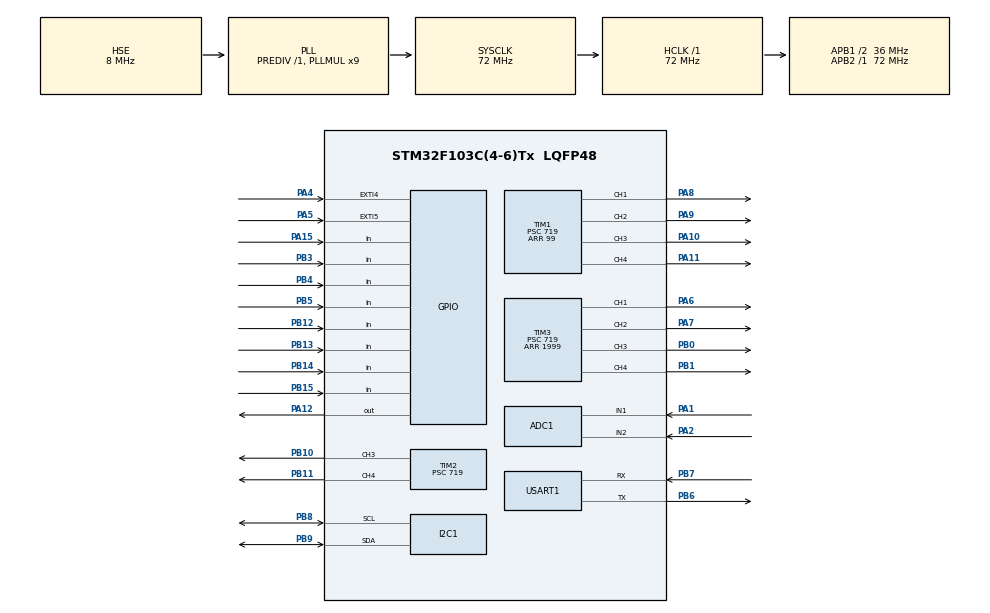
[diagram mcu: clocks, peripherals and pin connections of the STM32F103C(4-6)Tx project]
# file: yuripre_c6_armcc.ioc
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ADC1.Channel-0\#ChannelRegularConversion=ADC_CHANNEL_1
ADC1.NbrOfConversionFlag=1
ADC1.Rank-0\#ChannelRegularConversion=1
ADC1.SamplingTime-0\#ChannelRegularConversion=ADC_SAMPLETIME_1CYCLE_5
ADC1.master=1
Mcu.Family=STM32F1
Mcu.Name=STM32F103C(4-6)Tx
Mcu.Package=LQFP48
NVIC.PriorityGroup=NVIC_PRIORITYGROUP_4
PA1.Signal=ADCx_IN1
PA10.Signal=S_TIM1_CH3
PA11.Signal=S_TIM1_CH4
PA12.Signal=GPIO_Output
PA13.Mode=Serial_Wire
PA13.Signal=SYS_JTMS-SWDIO
PA14.Mode=Serial_Wire
PA14.Signal=SYS_JTCK-SWCLK
PA15.GPIO_PuPd=GPIO_PULLUP
PA15.Signal=GPIO_Input
PA2.Signal=ADCx_IN2
PA4.GPIO_ModeDefaultEXTI=GPIO_MODE_IT_FALLING
PA4.GPIO_PuPd=GPIO_PULLUP
PA4.Signal=GPXTI4
PA5.GPIO_ModeDefaultEXTI=GPIO_MODE_IT_FALLING
PA5.GPIO_PuPd=GPIO_PULLUP
PA5.Signal=GPXTI5
PA6.Signal=S_TIM3_CH1
PA7.Signal=S_TIM3_CH2
PA8.Signal=S_TIM1_CH1
PA9.Signal=S_TIM1_CH2
PB0.Signal=S_TIM3_CH3
PB1.Signal=S_TIM3_CH4
PB10.Signal=S_TIM2_CH3
PB11.Signal=S_TIM2_CH4
PB12.GPIO_PuPd=GPIO_PULLUP
PB12.Signal=GPIO_Input
PB13.GPIO_PuPd=GPIO_PULLUP
PB13.Signal=GPIO_Input
PB14.GPIO_PuPd=GPIO_PULLUP
PB14.Signal=GPIO_Input
PB15.GPIO_PuPd=GPIO_PULLUP
PB15.Signal=GPIO_Input
PB3.GPIO_PuPd=GPIO_PULLUP
PB3.Signal=GPIO_Input
PB4.GPIO_PuPd=GPIO_PULLUP
PB4.Signal=GPIO_Input
PB5.GPIO_PuPd=GPIO_PULLUP
PB5.Signal=GPIO_Input
PB6.Mode=Asynchronous
PB6.Signal=USART1_TX
PB7.Mode=Asynchronous
PB7.Signal=USART1_RX
PB8.Mode=I2C
PB8.Signal=I2C1_SCL
PB9.Mode=I2C
PB9.Signal=I2C1_SDA
PD0-OSC_IN.Mode=HSE-External-Oscillator
PD0-OSC_IN.Signal=RCC_OSC_IN
PD1-OSC_OUT.Mode=HSE-External-Oscillator
PD1-OSC_OUT.Signal=RCC_OSC_OUT
ProjectManager.HeapSize=0x200
ProjectManager.StackSize=0x400
ProjectManager.TargetToolchain=MDK-ARM V5.32
RCC.ADCPresc=RCC_ADCPCLK2_DIV6
RCC.AHBFreq_Value=72000000
RCC.APB1CLKDivider=RCC_HCLK_DIV2
RCC.APB1Freq_Value=36000000
RCC.APB1TimFreq_Value=72000000
RCC.APB2Freq_Value=72000000
RCC.APB2TimFreq_Value=72000000
RCC.HCLKFreq_Value=72000000
RCC.PLLMUL=RCC_PLL_MUL9
RCC.PLLSourceVirtual=RCC_PLLSOURCE_HSE
RCC.SYSCLKFreq_VALUE=72000000
RCC.SYSCLKSource=RCC_SYSCLKSOURCE_PLLCLK
RCC.USBFreq_Value=72000000
SH.ADCx_IN1.0=ADC1_IN1,IN1
SH.ADCx_IN2.0=ADC1_IN2,IN2
SH.S_TIM1_CH1.0=TIM1_CH1,PWM Generation1 CH1
SH.S_TIM1_CH2.0=TIM1_CH2,PWM Generation2 CH2
SH.S_TIM1_CH3.0=TIM1_CH3,PWM Generation3 CH3
SH.S_TIM1_CH4.0=TIM1_CH4,PWM Generation4 CH4
SH.S_TIM2_CH3.0=TIM2_CH3,PWM Generation3 CH3
SH.S_TIM2_CH4.0=TIM2_CH4,PWM Generation4 CH4
SH.S_TIM3_CH1.0=TIM3_CH1,PWM Generation1 CH1
SH.S_TIM3_CH2.0=TIM3_CH2,PWM Generation2 CH2
SH.S_TIM3_CH3.0=TIM3_CH3,PWM Generation3 CH3
SH.S_TIM3_CH4.0=TIM3_CH4,PWM Generation4 CH4
TIM1.AutoReloadPreload=TIM_AUTORELOAD_PRELOAD_ENABLE
TIM1.Channel-PWM\ Generation1\ CH1=TIM_CHANNEL_1
TIM1.Channel-PWM\ Generation2\ CH2=TIM_CHANNEL_2
TIM1.Channel-PWM\ Generation3\ CH3=TIM_CHANNEL_3
TIM1.Channel-PWM\ Generation4\ CH4=TIM_CHANNEL_4
TIM1.Period=99
TIM1.Prescaler=719
TIM2.AutoReloadPreload=TIM_AUTORELOAD_PRELOAD_ENABLE
TIM2.Channel-PWM\ Generation3\ CH3=TIM_CHANNEL_3
TIM2.Channel-PWM\ Generation4\ CH4=TIM_CHANNEL_4
TIM2.Period=1999
TIM2.Prescaler=719
TIM3.AutoReloadPreload=TIM_AUTORELOAD_PRELOAD_ENABLE
TIM3.Channel-PWM\ Generation1\ CH1=TIM_CHANNEL_1
TIM3.Channel-PWM\ Generation2\ CH2=TIM_CHANNEL_2
TIM3.Channel-PWM\ Generation3\ CH3=TIM_CHANNEL_3
TIM3.Channel-PWM\ Generation4\ CH4=TIM_CHANNEL_4
TIM3.Period=1999
TIM3.Prescaler=719
USART1.VirtualMode=VM_ASYNC
VP_TIM1_VS_ClockSourceINT.Mode=Internal
board=custom

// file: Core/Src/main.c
/* USER CODE BEGIN Header */
/**
  ******************************************************************************
  * @file           : main.c
  * @brief          : Main program body
  ******************************************************************************
  * @attention
  *
  * Copyright (c) 2022 STMicroelectronics.
  * All rights reserved.
  *
  * This software is licensed under terms that can be found in the LICENSE file
  * in the root directory of this software component.
  * If no LICENSE file comes with this software, it is provided AS-IS.
  *
  ******************************************************************************
  */
/* USER CODE END Header */
#include "main.h"
#include "adc.h"
#include "i2c.h"
#include "tim.h"
#include "usart.h"
#include "gpio.h"

/* USER CODE BEGIN Includes */
uint8_t  pwm;
/* USER CODE END Includes */

void SystemClock_Config(void);

int main(void)
{

  /* MCU Configuration--------------------------------------------------------*/

  /* Reset of all peripherals, Initializes the Flash interface and the Systick. */
  HAL_Init();

  /* Configure the system clock */
  SystemClock_Config();

  /* Initialize all configured peripherals */
  MX_GPIO_Init();
  MX_ADC1_Init();
  MX_I2C1_Init();
  MX_TIM1_Init();
  MX_TIM2_Init();
  MX_TIM3_Init();
  MX_USART1_UART_Init();

  /* Infinite loop */
  while (1)
  {

    /* USER CODE BEGIN 3 */
      HAL_GPIO_TogglePin(GPIOA, GPIO_PIN_12);
      HAL_Delay(100);
  }
  /* USER CODE END 3 */
}

void SystemClock_Config(void)
{
  RCC_OscInitTypeDef RCC_OscInitStruct = {0};
  RCC_ClkInitTypeDef RCC_ClkInitStruct = {0};
  RCC_PeriphCLKInitTypeDef PeriphClkInit = {0};

  /** Initializes the RCC Oscillators according to the specified parameters
  * in the RCC_OscInitTypeDef structure.
  */
  RCC_OscInitStruct.OscillatorType = RCC_OSCILLATORTYPE_HSE;
  RCC_OscInitStruct.HSEState = RCC_HSE_ON;
  RCC_OscInitStruct.HSEPredivValue = RCC_HSE_PREDIV_DIV1;
  RCC_OscInitStruct.HSIState = RCC_HSI_ON;
  RCC_OscInitStruct.PLL.PLLState = RCC_PLL_ON;
  RCC_OscInitStruct.PLL.PLLSource = RCC_PLLSOURCE_HSE;
  RCC_OscInitStruct.PLL.PLLMUL = RCC_PLL_MUL9;
  if (HAL_RCC_OscConfig(&RCC_OscInitStruct) != HAL_OK)
  {
    Error_Handler();
  }

  /** Initializes the CPU, AHB and APB buses clocks
  */
  RCC_ClkInitStruct.ClockType = RCC_CLOCKTYPE_HCLK|RCC_CLOCKTYPE_SYSCLK
                              |RCC_CLOCKTYPE_PCLK1|RCC_CLOCKTYPE_PCLK2;
  RCC_ClkInitStruct.SYSCLKSource = RCC_SYSCLKSOURCE_PLLCLK;
  RCC_ClkInitStruct.AHBCLKDivider = RCC_SYSCLK_DIV1;
  RCC_ClkInitStruct.APB1CLKDivider = RCC_HCLK_DIV2;
  RCC_ClkInitStruct.APB2CLKDivider = RCC_HCLK_DIV1;

  if (HAL_RCC_ClockConfig(&RCC_ClkInitStruct, FLASH_LATENCY_2) != HAL_OK)
  {
    Error_Handler();
  }
  PeriphClkInit.PeriphClockSelection = RCC_PERIPHCLK_ADC;
  PeriphClkInit.AdcClockSelection = RCC_ADCPCLK2_DIV6;
  if (HAL_RCCEx_PeriphCLKConfig(&PeriphClkInit) != HAL_OK)
  {
    Error_Handler();
  }
}

void Error_Handler(void)
{
  __disable_irq();
  while (1)
  {
  }
}
